# SPC1169 register map
File version: 2022071043481212
CPU: cm4 r1p0, little endian, no MPU, FPU, 4 interrupt priority bits
Registers are 32-bit, read-write, reset 0x0 unless marked. A register's access mark holds for its fields unless they carry their own. Offsets are from the block's base; [hi:lo] are bit positions; {n}, {i} and the like mark numbered series; 'fields as' and 'values as' point back to an identical list.

## UART0
Base 0x40001400
Same registers: UART1 0x40001600
0x00 UARTDAT — UART Data Register
  [31:0] VAL — Data transmitted or received on the UART bus. A write to the register accesses the transmit hold register to set the data to be transmitted. A read to the register accesses the receive buffer register to get the received data
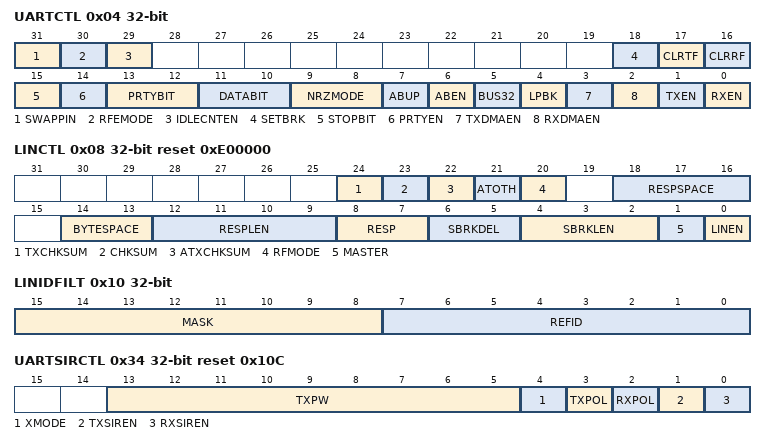
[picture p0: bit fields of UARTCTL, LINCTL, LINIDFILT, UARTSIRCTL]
0x04 UARTCTL — UART Control Register
  [31] SWAPPIN — Swap TXD and RXD pin function
    0=ORIGINAL_FUNCTION (Transmit data via TXD and receive data via RXD); 1=SWAP_FUNCTION (Transmit data via RXD and receive data via TXD)
  [30] RFEMODE — Receive FIFO error report mode
    0=REPORT_IF_WRITABLE (Report frame error, parity error and break indicator only when the FIFO is not full and data is writable); 1=REPORT_ALL (Report frame error, parity error and break indicator upon event regardless of FIFO status)
  [29] IDLECNTEN — Bus idle counter enable
    0=DISABLE; 1=ENABLE
  [18] SETBRK — Set Break. Causes a break condition to be transmitted to the receiving UART. Acts only on the TXD pin and has no effect on the transmit logic. In FIFO mode, wait until the transmitter is idle (UARTSTS.TXDONE=1) to set and clear SB.
    0=NO_EFFECT (No effect on TXD output); 1=SET_BREAK (This bit is self cleared when the UART starts to transmit the break condition. If software write this bit again before the current break condition is stop transmitting, TXD pin will keep low for the new frame. i.e. The receiver sees single break condition with bus is holding low for multiple frame duration.)
  [17] CLRTF — Clear the transmit FIFO. The transmit shift register is not affected by this bit, and it completes the current transmission.
    0=NO_EFFECT (Write a 0 has no effect and always read back 0); 1=CLEAR (Write a 1 clears the transmit FIFO and sets TXDREQ flag. This bit is self-cleared)
  [16] CLRRF — Clear the receive FIFO
    0=NO_EFFECT (Write a 0 has no effect and always read back 0); 1=CLEAR (Write a 1 clears the receive FIFO and RXDAV flag. This bit is self-cleared)
  [15] STOPBIT — Stop bits
    0=1_STOP_BIT; 1=2_STOP_BIT (1.5 stop bits for 5-bit character. 2 stop bits for 6/7/8 bit character)
  [14] PRTYEN — Parity enable
    0=PARITY_DISABLE (Disable parity bit for UART mode and disable ID parity check for LIN); 1=PARITY_ENABLE (Enable parity bit for UART mode and enable ID parity check for LIN)
  [13:12] PRTYBIT — Parity bit mode
    0=EVEN_PARITY (Sends or checks for even parity); 1=ODD_PARITY (Sends or checks for odd parity); 2=STICKY_HIGH_PARITY (Sends or checks for sticky high parity); 3=STICKY_LOW_PARITY (Sends or checks for sticky low parity)
  [11:10] DATABIT — Data bits of each character
    {v}={v+5}_DATA_BIT ({v+5}-bit character) (v=0..3)
  [9:8] NRZMODE — NRZ coding mode. This bit is ignored in serail infra-red (SIR) mode and general NRZ level is always used.
    0=NRZ_LEVEL (NRZ level coding. High level for 1 and low level for 0.); 2=NRZ_SPACE (NRZ space coding. Keep constant on 1 and toggle on 0.); 3=NRZ_MARK (NRZ mark coding. Keep constant on 0 and toggle on 1.)
  [7] ABUP — Auto baud count update option
    0=UPDATE_BY_HW (Baud counter is updated by the hardware); 1=UPDATE_BY_SW (Baud counter is updated by the software)
  [6] ABEN — Auto baud enable
    0=DISABLE (Disable auto baud); 1=ENABLE (Enable auto baud)
  [5] BUS32 — 32-Bit bus width
    0=8BIT (8-bit peripheral bus); 1=32BIT (32-bit peripheral bus)
  [4] LPBK — Loopback mode for diagnostic testing as below (1) Set the transmitter serial output to logic 1 state (2) Disconnect the receiver serial input from pin. (3) Transmitted data is received immediately. The output of the Transmit Shift Register is looped back into the Receive Shift Register input. (4) Support transferring a break signal from the transmitter section to the receiver section. This bit must be configured before UART is enabled
    0=NORMAL_MODE (Normal UART operation); 1=LOOPBACK_MODE (Loopback-mode UART operation)
  [3] TXDMAEN — Transmit DMA requests enable
    0=DISABLE (Disable DMA for UART transmitter); 1=ENABLE (Enable DMA for UART transmitter)
  [2] RXDMAEN — Receive DMA requests enable
    0=DISABLE (Disable DMA for UART receiver); 1=ENABLE (Enable DMA for UART receiver)
  [1] TXEN — UART transmit enable
    0=DISABLE (Disable UART transmit); 1=ENABLE (Enable UART transmit)
  [0] RXEN — UART receive enable
    0=DISABLE (Disable UART receive); 1=ENABLE (Enable UART receive)
0x08 LINCTL reset 0xE00000 — LIN Control Register
  [24] TXCHKSUM — One-shot checksum transmit request
    0=NO_EFFECT (Write 0 has no effect and read back 0 after checksum is transmitted); 1=TRANSMIT (Write 1 will request to transmit the checksum. If the data field is already finished, the checksum will be transmitted immediately. If the data field is not finished, the request is pended and the checksum will be transmitted right after the data field is done)
  [23] CHKSUM — Checksum mode
    0=CLASSIC_MODE (Classic checksum is used so the checksum contains the modulo-256 sum with carry over all data bytes); 1=ENHANCED_MODE (Enhanced checksum is used so the checksum contains the modulo-256 sum with carry over all data bytes and the protected ID.)
  [22] ATXCHKSUM — Auto transmit checksum
    0=MANUAL_TX (Checksum is transmitted by manual request via writing 1 to TXCHKSUM bit); 1=AUTO_TX (Checksum is transmitted automatically after the data field)
  [21] ATOTH — Auto timeout threshold
    0=MANUAL_THRESHOLD (The threshold is manually specified via UARTTOTH); 1=AUTO_THRESHOLD (The threshold is automatically set according to LIN standard, namely the minimum required transmission time plus 40% margin)
  [20] RFMODE — Receive FIFO operation mode
    0=SAVE_ALL_DATA_AND_CHECKSUM (The frame data as well as the checksum byte will be saved in the RX FIFO regardless whether the checksum is correct. This is useful to debug the checksum error); 1=SAVE_CORRECT_DATA (The frame data will saved in the RX FIFO only when the checksum is correct)
  [18:16] RESPSPACE — Response space (number of bauds)
  [14:13] BYTESPACE — Inter-byte space (number of bauds)
  [12:9] RESPLEN — Response data length
    0=X_BYTE (The repsonse data field length is decide by LINID[5:4]. 11: 8-byte; 10: 4-byte; Other: 2-byte); {v}={v}_BYTE (The repsonse data field has {v}-byte) (v=1..8)
  [8:7] RESP — Response to take
    0=RESPONSE_NONE (Do not response in the frame); 1=RESPONSE_RX (Receive data in the frame); 2=RESPONSE_TX (Transmit data in the frame); 3=RESPONSE_TR (Transmit and receive data in the frame (For debug purpose))
  [6:5] SBRKDEL — Synchronize break delimiter
    {v}={v+1}_BIT (Synch break delimiter is {v+1}-bit recessive) (v=0..3)
  [4:2] SBRKLEN — Synchronize break length
    {v}={v+13}_BIT (Synch break is {v+13}-bit dominant) (v=0..7)
  [1] MASTER — LIN node role
    0=SLAVE (Slave node); 1=MASTER (Mater node)
  [0] LINEN — LIN mode enable
    0=UART_MODE (Disable LIN mode); 1=LIN_MODE (Enable LIN mode)
0x0C LINID
  [7:0] ID — LIN ID. Write to this register set the ID to be transmitted. Read from this register get the received ID
0x10 LINIDFILT — LIN ID Filter Register
  [15:8] MASK — LIN ID mask. It indicates whether the corresponding bit in REFID is used for comparison. 0: Not compare; 1: Compare
  [7:0] REFID — LIN ID reference for the compare
0x14 BUSIDLETH reset 0xFFFFFFFF — Bus Idle Threshold Register
  [31:0] VAL — Number of AHB clock cycles to report bus idle (no activity on the RXD)
0x18 UARTBDCNT reset 0x10 — UART Baud Count Register
  [15:0] VAL — UART baud rate will be UART clock / UARTBDCNT. The minimum valid value is 16 and write a value below 16 will be reset to 16.
0x1C UARTABCNT ro — UART Auto-Baud Count Register
  [15:0] VAL — Number of UART clock cycles within a start-bit pulse
0x20 UARTTOTH reset 0x30 — UART Timeout Threshold Register
  [7:0] VAL — Number of UART baud cycles for the specified condition to keep before the timeout event is generated. The minimum allowed number is 1. Write a value as 0 will be reset to 1. For UART mode, the condition is that there is unread received data in the FIFO and the RXD bus keeps high. For LIN mode, the condition is that the received data length is below the expectation when the response field is timeout
0x24 UARTRXLVL ro — UART Receive FIFO Level Register
  [6:0] VAL — Number of bytes (0-64) remaining in the Receive FIFO
0x28 UARTTXLVL ro — UART Transmit FIFO Level Register
  [6:0] VAL — Number of bytes (0-64) remaining in the Transmit FIFO
0x2C UARTRXTH — UART Receive FIFO Threshold Register
  [5:0] VAL — Trigger receive data available interrupt when UARTRFLVL>UARTRFTH
0x30 UARTTXTH — UART Transmit FIFO Threshold Register
  [5:0] VAL — Trigger transmit data request interrupt when UARTTFLVL<=UARTTFTH
0x34 UARTSIRCTL reset 0x10C — UART Infrared Control Register
  [13:5] TXPW — Transmit pulse width. The minimum allowed value is 1. Write a 0 will be reset as 1 by hardware.
  [4] XMODE — Transmit pulse width select
    0=WIDTH_3_OVER_16 (Transmit pulse width has a constant duty cycle as 3/16 bit time); 1=WIDTH_TXPW_CYCLES (Transmit pulse width has a constant width as TXPW UART clock cycles)
  [3] TXPOL — Transmit data polarity
    0=NEGATIVE_PULSE_AS_ZERO (SIR encoder generates a negative pulse for a data bit of zero); 1=POSITIVE_PULSE_AS_ZERO (SIR encoder generates a positive pulse for a data bit of zero)
  [2] RXPOL — Receive data polarity
    0=NEGATIVE_PULSE_AS_ZERO (SIR decoder takes negative pulses as zeros); 1=POSITIVE_PULSE_AS_ZERO (SIR decoder takes positive pulses as zeros)
  [1] TXSIREN — Transmitter SIR enable
    0=UART (Transmitter is in UART mode. All clocking to the lrDA encoder is blocked and the UART's TXD signal is connected directly to the device pin.); 1=INFRARED (Transmitter is in infrared mode. The normal TXD output from the UART is processed by the lrDA encoder before it is fed to the device pin.)
  [0] RXSIREN — Receiver SIR enable
    0=UART (Receiver is in UART mode. All clocking to the lrDA decoder is blocked and the RXD pin is fed directly to the UART.); 1=INFRARED (Receiver is in infrared mode. The signal from the RXD pin is processed by lrDA decoder before it is fed to the UART.)
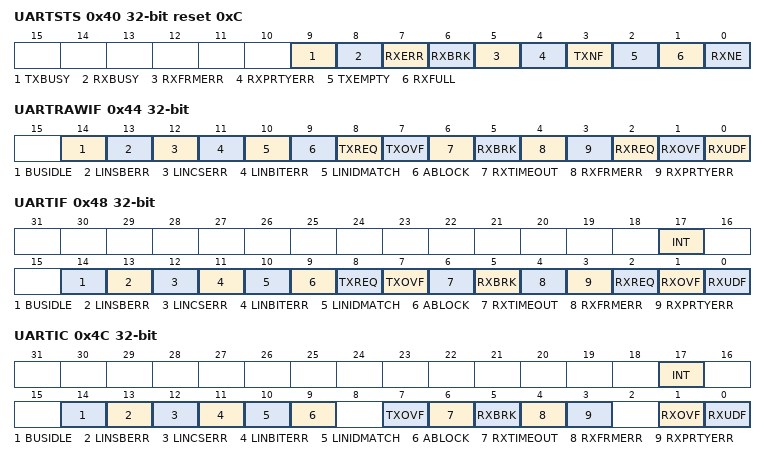
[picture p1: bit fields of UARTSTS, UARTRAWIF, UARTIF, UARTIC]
0x40 UARTSTS ro reset 0xC — UART Status Register
  [9] TXBUSY — Indicate the UART is transmitting
    0=IDLE (The UART transmitter is in idle state); 1=BUSY (The UART transmitter is busy)
  [8] RXBUSY — Indicate the UART is receiving
    0=IDLE (The UART receiver is in idle state); 1=BUSY (The UART receiver is busy)
  [7] RXERR — Indicate there is parity error, frame error or break condition for the un-read data in the receive FIFO
    0=CORRECT (Data in receive FIFO are all error-free); 1=ERROR (There is error for un-read data in the receive FIFO)
  [6] RXBRK — Break condition indicator for the data just read out from the receive FIFO. For 32-bit bus, this bit is the logic OR of the break condition for all bytes read.
    0=NORMAL_DATA (The all "0" byte read from UARTDAT is a normal data); 1=BREAK_CONDITION (The all "0" byte read from UARTDAT is due to a break condition)
  [5] RXFRMERR — Frame error indicator for the data just read out from the receive FIFO. For 32-bit bus, this bit is the logic OR of the frame error for all bytes read.
    0=CORRECT (No frame error for the data read out via UARTDAT); 1=ERROR (Frame error for the data read out via UARTDAT)
  [4] RXPRTYERR — Parity error indicator for the data just read out from the receive FIFO. For 32-bit bus, this bit is the logic OR of the parity error for all bytes read.
    0=CORRECT (No parity error for the data read out via UARTDAT); 1=ERROR (Parity error for the data read out via UARTDAT)
  [3] TXNF — Transmit FIFO not full (i.e. UARTTFLVL<64)
    0=FULL (Transmit FIFO is full); 1=NOT_FULL (Transmit FIFO contains empty locations)
  [2] TXEMPTY — Transmit FIFO empty
    0=NOT_EMPTY (Transmit FIFO contains one ore more data entries); 1=EMPTY (Transmit FIFO is completely empty. But there may be still data in the transmit shift out register and the transmit is going on.)
  [1] RXFULL — Receive FIFO full
    0=NOT_FULL (Receive FIFO contains empty locations); 1=FULL (Receive FIFO is completely full)
  [0] RXNE — Receive FIFO not empty (i.e. UARTRFLVL>0)
    0=EMPTY (Receive FIFO is empty); 1=NOT_EMPTY (Receive FIFO contains one or more data entries)
0x44 UARTRAWIF ro — UART Raw Interrupt Flag Register
  [14] BUSIDLE — LIN bus idle raw flag
    0=NOT_OCCUR (Event does not occur); 1=OCCUR (Event occurred)
  [13] LINSBERR — LIN received sync byte error raw flag
    0=NOT_OCCUR (Event does not occur); 1=OCCUR (Event occurred)
  [12] LINCSERR — LIN checksum error interrup raw flag
    0=NOT_OCCUR (Event does not occur); 1=OCCUR (Event occurred)
  [11] LINBITERR — LIN bit error interrupt raw flag
    0=NOT_OCCUR (Event does not occur); 1=OCCUR (Event occurred)
  [10] LINIDMATCH — LIN received ID match interrupt raw flag
    0=NOT_OCCUR (Event does not occur); 1=OCCUR (Event occurred)
  [9] ABLOCK — Auto-baud lock interrupt raw flag
    0=NOT_OCCUR (Event does not occur); 1=OCCUR (Event occurred)
  [8] TXREQ — Transmit data write request interrupt raw flag
    0=NOT_OCCUR (Read a 0 indicates there is enough data in the transmit FIFO. It will be set to 1 once UARTTXLVL<=UARTTXTH); 1=OCCUR (Read a 1 indicates the transmit FIFO requests more data. It will be cleared to 0 once UARTTXLVL>UARTTXTH)
  [7] TXOVF — Transmit overflow interrupt raw flag. It indicates an attempt to write UARTDAT when transmit FIFO is full
    0=NOT_OCCUR (Event occurred); 1=OCCUR (Event does not occur)
  [6] RXTIMEOUT — Receive time out interrupt raw flag. For LIN mode, it indicates timeout for the response field
    0=NOT_OCCUR (Event occurred); 1=OCCUR (Event does not occur)
  [5] RXBRK — Receive break condition interrupt raw flag. This bit is set once a break condition is received
    0=NOT_OCCUR (Event occurred); 1=OCCUR (Event does not occur)
  [4] RXFRMERR — Receive frame error interrupt raw flag. This bit is set once a frame error (stop bit is low) is received
    0=NOT_OCCUR (Event occurred); 1=OCCUR (Event does not occur)
  [3] RXPRTYERR — Receive parity error interrupt raw flag. This bit is set once a parity error is received. In LIN mode, it indicates parity error for the PID
    0=NOT_OCCUR (Event occurred); 1=OCCUR (Event does not occur)
  [2] RXREQ — Receive data read request interrupt raw flag
    0=NOT_OCCUR (Read a 0 indicates there are not enough data in the receive FIFO. It will be set to 1 once UARTRXLVL>UARTRXTH); 1=OCCUR (Read a 1 indicates there are enough data in the receive FIFO. It will be cleared to 0 once UARTRXLVL<=UARTRXTH)
  [1] RXOVF — Receive overflow interrupt raw flag. It indicates a new character is received when the receive FIFO is full and the new data is dropped.
    0=NOT_OCCUR (Event occurred); 1=OCCUR (Event does not occur)
  [0] RXUDF — Receive underflow interrupt raw flag. It indicates an attempt to read UARTDAT when the receive FIFO is empty
    0=NOT_OCCUR (Event occurred); 1=OCCUR (Event does not occur)
0x48 UARTIF ro — UART Interrupt Flag Register
  [17] INT — Global interrupt flag
    0=NOT_OCCUR (Interrupt is never triggerred); 1=OCCUR (Interrupt is triggered and issued to the CPU. Further interrupt pulse to the CPU will not be generated until this bit is cleared.)
  [14] BUSIDLE — Bus idle interrupt flag
    0=NOT_OCCUR (Interrupt is never triggerred); 1=OCCUR (Interrupt is triggered and issued to the CPU. Further event will not trigger interrupt until this bit is cleared.)
  [13] LINSBERR — LIN sync byte error interrupt flag
    values as BUSIDLE
  [12] LINCSERR — LIN checksum error interrupt flag. This bit is always 0 if UARTIE_LINCSERR=0
    values as BUSIDLE
  [11] LINBITERR — LIN bit error interrupt flag. This bit is always 0 if UARTIE_LINBITERR=0
    values as BUSIDLE
  [10] LINIDMATCH — LIN received ID match interrupt flag. This bit is always 0 if UARTIE_LINIDMATCH=0
    values as BUSIDLE
  [9] ABLOCK — Auto-baud lock interrupt flag. This bit is always 0 if UARTIE_ABLOCK=0
    values as BUSIDLE
  [8] TXREQ — Transmit data write request interrupt flag. This bit is always 0 if UARTIE_TXREQ=0
    values as BUSIDLE
  [7] TXOVF — Transmit overflow interrupt flag. This bit is always 0 if UARTIE_RXOVF=0
    values as BUSIDLE
  [6] RXTIMEOUT — Time out detected interrupt flag. This bit is always 0 if UARTIE_RXTIMEOUT=0
    values as BUSIDLE
  [5] RXBRK — Receive break condition interrupt flag. This bit is always 0 if UARTIE_RXBRK=0
    values as BUSIDLE
  [4] RXFRMERR — Receive frame error interrupt flag. This bit is always 0 if UARTIE_RXFRMERR=0
    values as BUSIDLE
  [3] RXPRTYERR — Receive parity error interrupt flag. This bit is always 0 if UARTIE_RXPRTYERR=0
    values as BUSIDLE
  [2] RXREQ — Receive data read request interrupt flag. This bit is always 0 if UARTIE_RXREQ=0
    values as BUSIDLE
  [1] RXOVF — Receive overflow interrupt flag. This bit is always 0 if UARTIE_RXOVF=0
    values as BUSIDLE
  [0] RXUDF — Receive underflow interrupt flag. This bit is always 0 if UARTIE_RXUDF=0
    values as BUSIDLE
0x4C UARTIC — UART Interrupt Clear Register
  [all] fields
    0=NO_EFFECT (Write 0 has no effect and always read back 0); 1=CLEAR (Write 1 clears the flag. This bit is self cleared.)
  [17] INT — Global interrupt clear
  [14] BUSIDLE — Bus idle interrupt clear
  [13] LINSBERR — LIN sync byte error interrupt clear
  [12] LINCSERR — LIN checksum error interrupt clear
  [11] LINBITERR — LIN bit error interrupt clear
  [10] LINIDMATCH — LIN received ID match interrupt clear
  [9] ABLOCK — Auto-baud lock interrupt clear
  [7] TXOVF — Transmit overflow interrupt clear
  [6] RXTIMEOUT — Receive timeout interrupt clear
  [5] RXBRK — Receive break condition interrupt clear
  [4] RXFRMERR — Receive frame error interrupt clear
  [3] RXPRTYERR — Receive parity error interrupt clear
  [1] RXOVF — Receive overflow interrupt clear
  [0] RXUDF — Receive underflow interrrupt clear
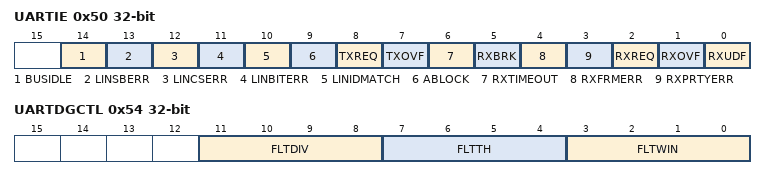
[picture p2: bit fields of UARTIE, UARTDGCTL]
0x50 UARTIE — UART Interrupt Enable Register
  [all] fields
    0=DISABLE; 1=ENABLE
  [14] BUSIDLE — Bus idle interrupt enable
  [13] LINSBERR — LIN sync byte error interrupt enable
  [12] LINCSERR — LIN checksum error interrupt enable
  [11] LINBITERR — LIN bit error interrupt enable
  [10] LINIDMATCH — LIN received ID match interrupt enable
  [9] ABLOCK — Auto-baud lock interrupt enable
  [8] TXREQ — Transmit data write request interrupt enable
  [7] TXOVF — Transmit overflow interrupt enable
  [6] RXTIMEOUT — Receive timeout interrupt enable
  [5] RXBRK — Receive break condition interrupt enable
  [4] RXFRMERR — Receive frame error interrupt enable
  [3] RXPRTYERR — Receive parity error interrupt enable
  [2] RXREQ — Receive data read request interrupt enable
  [1] RXOVF — Receive overflow interrupt enable
  [0] RXUDF — Receive underflow interrupt enable
0x54 UARTDGCTL — UART RXD Deglitch Control
  [11:8] FLTDIV — Deglitch filter clock dividing ratio, which is (FLTDIV+1)
  [7:4] FLTTH — Deglitch filter threshold is (FLTTH+1) 1's/0's for output to toggle
  [3:0] FLTWIN — Deglitch filter window size is (FLTWIN+1) samples
0x58 UARTREGKEY reset 0x1ACCE551 — Uart Register Write-Allow Key Register
  [31:0] KEY — Write 0x1ACCE551 to unlock protected UART registers
